VERSION ""

NS_ :

BS_:

BU_: XXX

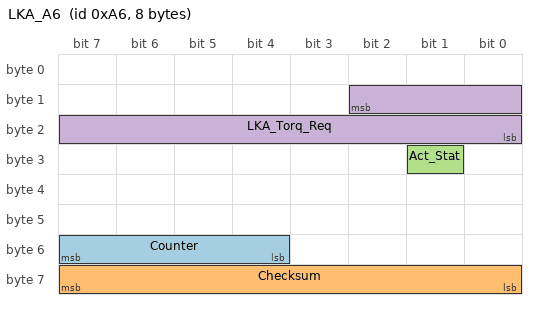
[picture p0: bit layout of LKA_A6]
BO_ 166 LKA_A6: 8 XXX
 SG_ Counter : 55|4@0+ (1,0) [0|15] "" XXX
 SG_ Checksum : 63|8@0+ (1,0) [0|255] "" XXX
 SG_ Act_Stat : 25|1@0+ (1,0) [0|1] "" XXX
 SG_ LKA_Torq_Req : 10|11@0+ (1,-1024) [0|7] "" XXX

BO_ 121 VS_79: 8 XXX
 SG_ Counter : 55|4@0+ (1,0) [0|15] "" XXX
 SG_ Checksum : 63|8@0+ (1,0) [0|255] "" XXX
 SG_ VS : 39|16@0+ (1,0) [0|255] "" XXX
 SG_ UNKNOWN1 : 2|11@0+ (1,0) [0|255] "" XXX
 SG_ UNKNOWN2 : 18|13@0+ (1,0) [0|65535] "" XXX
 SG_ Stationary_FLAG : 7|1@0+ (1,0) [0|1] "" XXX
